# 3067M register map
File version: 1.0
Registers are 32-bit, access per field, reset 0x0 unless marked. A register's access mark holds for its fields unless they carry their own. Offsets are from the block's base; [hi:lo] are bit positions; {n}, {i} and the like mark numbered series.

## ADC0 — ADC0 peripheral interface
Base 0x18000000
Same registers: ADC1 0x18001000, ADC2 0x18002000, ADC3 0x18003000
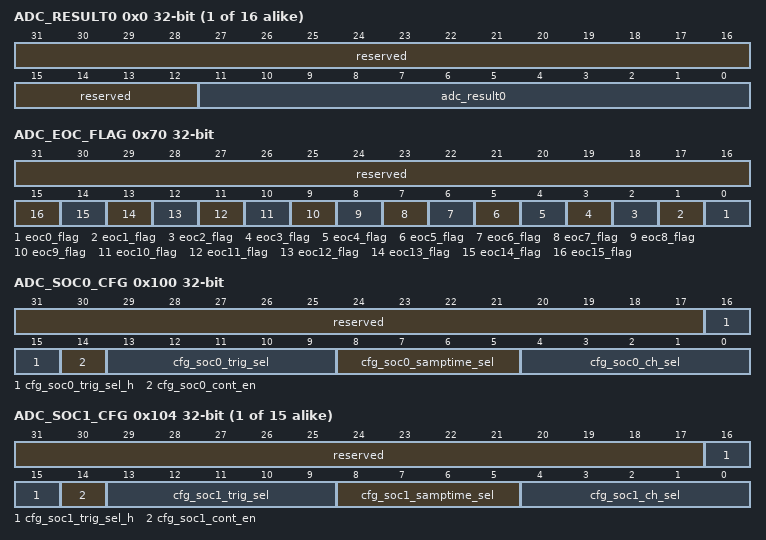
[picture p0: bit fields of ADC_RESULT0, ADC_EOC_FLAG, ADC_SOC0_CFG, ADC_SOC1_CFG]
{0x0+4i} ADC_RESULT{i} ro (i=0..15) — ADC_RESULT{i}为ADC结果寄存器{i}。
  [31:12] reserved — 保留。
  [11:0] adc_result{i} — SOC{i}结果寄存器。
0x70 ADC_EOC_FLAG — ADC_EOC_FLAG为ADC eoc状态寄存器。
  [31:16] reserved ro — 保留。
  [n] eoc{n}_flag rw write-clears (n=0..15) — SOC{n}的EOC标志寄存器。
0x100 ADC_SOC0_CFG — ADC_SOC0_CFG为ADC SOC0配置寄存器。
  [31:17] reserved ro — 保留。
  [16:15] cfg_soc0_trig_sel_h rw — SOC0触发源选择。cfg_soc0_trig_sel_h和cfg_soc0_trig_sel共同控制触发源选择。具体参见27.5.2 触发源配置。
  [14] cfg_soc0_cont_en rw — SOC0连续转换模式使能。 0：不使能； 1：使能。
  [13:9] cfg_soc0_trig_sel rw — SOC0触发源选择。cfg_soc0_trig_sel_h和cfg_soc0_trig_sel共同控制触发源选择。具体参见27.5.2 触发源配置。
  [8:5] cfg_soc0_samptime_sel rw — SOC0采样周期选择。 0x0：5clk； 0x1：7clk； 0x2：10clk； 0x3：12clk； 0x4：15clk； 0x5：22clk； 0x6：30clk； 0x7：50clk； 0x8：75clk； 0x9：100clk； 0xA：125clk； 0xB：150clk； 0xC：200clk； 0xD：300clk； 0xE：400clk； 0xF：500clk。
  [4:0] cfg_soc0_ch_sel rw — SOC0通道选择。具体请参见27.2.5 输入信号。
{0x100+4i} ADC_SOC{i}_CFG (i=1..15) — ADC_SOC{i}_CFG为ADC SOC{i}配置寄存器。
  [31:17] reserved ro — 保留。
  [16:15] cfg_soc{i}_trig_sel_h rw — SOC{i}触发源选择。
  [14] cfg_soc{i}_cont_en rw — SOC{i}连续转换模式使能。
  [13:9] cfg_soc{i}_trig_sel rw — SOC{i}触发源选择。
  [8:5] cfg_soc{i}_samptime_sel rw — SOC{i}采样周期选择。
  [4:0] cfg_soc{i}_ch_sel rw — SOC{i}通道选择。
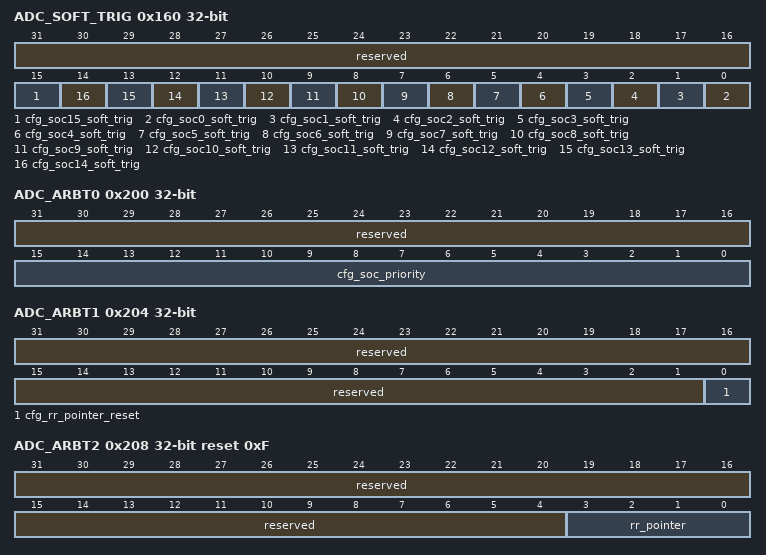
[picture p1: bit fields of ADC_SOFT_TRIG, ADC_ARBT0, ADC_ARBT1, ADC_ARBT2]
0x160 ADC_SOFT_TRIG — ADC_SOFT_TRIG为ADC软件触发寄存器。
  [31:16] reserved ro — 保留。
  [15] cfg_soc15_soft_trig rw write-1-clears — SOC15软件触发。 0：不触发； 1：触发脉冲。
  [n] cfg_soc{n}_soft_trig rw write-1-clears (n=0..14) — SOC{n}软件触发。
0x200 ADC_ARBT0 — ADC_ARBT0为ADC优先级寄存器0。
  [31:16] reserved ro — 保留。
  [15:0] cfg_soc_priority rw — SOC优先级组配置（配置对应bit位的SOC为高优先级组）。 0：轮询优先级组； 1：高优先级组。
0x204 ADC_ARBT1 — ADC_ARBT1为ADC优先级寄存器1。
  [31:1] reserved ro — 保留。
  [0] cfg_rr_pointer_reset rw write-1-clears — 轮询指针重置。 0：不重置； 1：重置指针到15。
0x208 ADC_ARBT2 ro reset 0xF — ADC_ARBT2为ADC优先级寄存器2。
  [31:4] reserved — 保留。
  [3:0] rr_pointer — 轮询指针位置。
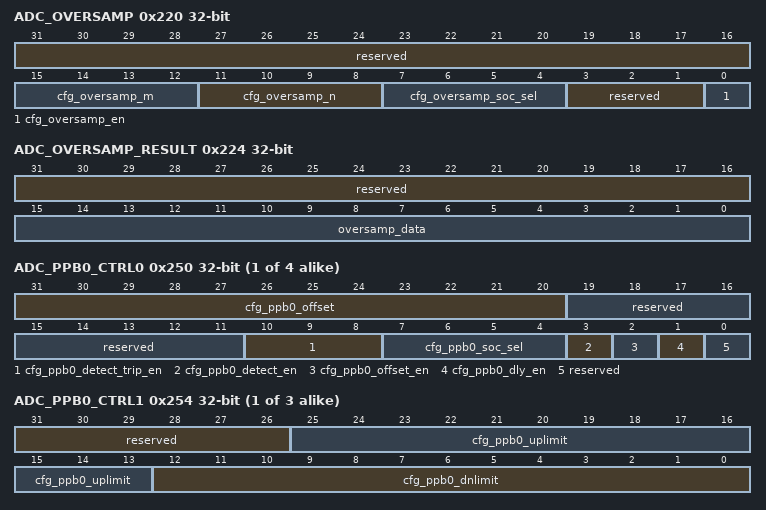
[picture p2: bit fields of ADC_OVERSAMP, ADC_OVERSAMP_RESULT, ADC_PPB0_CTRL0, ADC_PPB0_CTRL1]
0x220 ADC_OVERSAMP — ADC_OVERSAMP为ADC过采样配置寄存器。
  [31:16] reserved ro — 保留。
  [15:12] cfg_oversamp_m rw — 过采样截取精度选择，与cfg_oversamp_n联合配置，配置方式请参见27.8 过采样。
  [11:8] cfg_oversamp_n rw — 过采样累积倍数选择。 0x3：8倍； 0x4：16倍； 0x5：32倍； 0x6：64倍； 0x7：128倍； 0x8：256倍； 0x9：512倍； 0xA：1024倍； 0xB：2048倍； 其他：保留。
  [7:4] cfg_oversamp_soc_sel rw — 过采样SOC选择。 0x0：SOC0； 0x1：SOC1； … 0xF：SOC15。
  [3:1] reserved ro — 保留。
  [0] cfg_oversamp_en rw — 过采样使能。 0：不使能； 1：使能。
0x224 ADC_OVERSAMP_RESULT ro — ADC_OVERSAMP_RESULT为ADC过采样结果寄存器。
  [31:16] reserved — 保留。
  [15:0] oversamp_data — 过采样结果，低位（12bit~16bit）为有效精度。
{0x250+0x10*i} ADC_PPB{i}_CTRL0 (i=0..3) — ADC_PPB{i}_CTRL0为ADC后处理模块{i}配置寄存器0。
  [31:20] cfg_ppb{i}_offset rw — 后处理补偿offset值（有符号数，二进制补码，1bit符号位，11bit整数位）。
  [19:11] reserved ro — 保留。
  [10:8] cfg_ppb{i}_detect_trip_en rw — 后处理TRIP使能。对应bit配置1表示使能。 bit[10]：使能上阈值超限ppb{i}_uplimit_det触发ADC_EVEVT_TRIP{i}； bit[9]：使能下阈值超限ppb{i}_dnlimit_det触发ADC_EVEVT_TRIP{i}； bit[8]：使能过零点ppb{i}_zero_det触发ADC_EVEVT_TRIP{i}。
  [7:4] cfg_ppb{i}_soc_sel rw — 后处理模块SOC选择。 0x0：SOC0； 0x1：SOC1； … 0xF：SOC15。
  [3] cfg_ppb{i}_detect_en rw — 后处理阈值检测使能。 0：不使能； 1：使能。
  [2] cfg_ppb{i}_offset_en rw — 后处理offset补偿使能。 0：不使能； 1：使能。
  [1] cfg_ppb{i}_dly_en rw — 后处理采样延迟计数使能。 0：不使能； 1：使能。
  [0] reserved ro — 保留。
{0x254+0x10*i} ADC_PPB{i}_CTRL1 (i=0..2) — ADC_PPB{i}_CTRL1为ADC后处理模块{i}配置寄存器1。
  [31:26] reserved ro — 保留。
  [25:13] cfg_ppb{i}_uplimit rw — 后处理误差检测上限阈值（有符号数，二进制补码，1bit符号位，12bit整数位）。
  [12:0] cfg_ppb{i}_dnlimit rw — 后处理误差检测下限阈值（有符号数，二进制补码，1bit符号位，12bit整数位）。
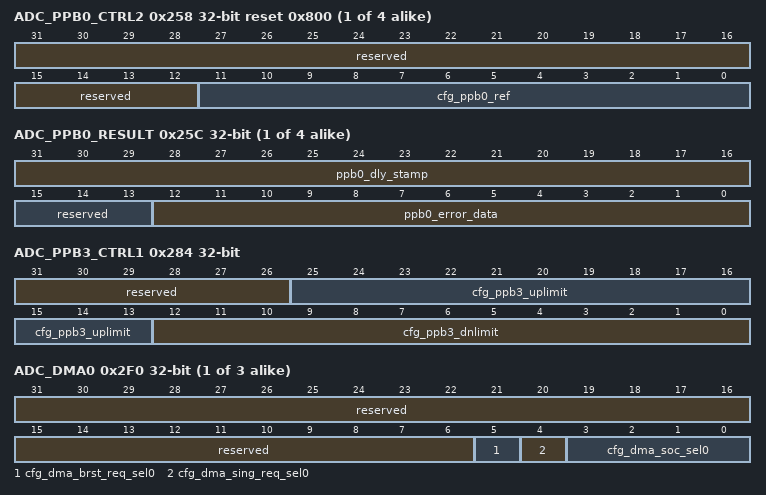
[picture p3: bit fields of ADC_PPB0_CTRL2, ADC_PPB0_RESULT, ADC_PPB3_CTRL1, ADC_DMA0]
{0x258+0x10*i} ADC_PPB{i}_CTRL2 reset 0x800 (i=0..3) — ADC_PPB{i}_CTRL2为ADC后处理模块{i}配置寄存器2。
  [31:12] reserved ro — 保留。
  [11:0] cfg_ppb{i}_ref rw — 后处理误差参考值（无符号数，12bit整数位）。
{0x25C+0x10*i} ADC_PPB{i}_RESULT ro (i=0..3) — ADC_PPB{i}_RESULT为ADC后处理模块{i}结果寄存器。
  [31:16] ppb{i}_dly_stamp — 后处理采样延迟计数值。
  [15:13] reserved — 保留。
  [12:0] ppb{i}_error_data — 后处理误差计算结果（有符号数，二进制补码，1bit符号位，12bit整数位）。
0x284 ADC_PPB3_CTRL1 — ADC_PPB3_CTRL1为ADC后处理模块3配置寄存器2。
  [31:26] reserved ro — 保留。
  [25:13] cfg_ppb3_uplimit rw — 后处理误差检测上限阈值（有符号数，二进制补码，1bit符号位，12bit整数位）。
  [12:0] cfg_ppb3_dnlimit rw — 后处理误差检测下限阈值（有符号数，二进制补码，1bit符号位，12bit整数位）。
{0x2F0+4i} ADC_DMA{i} (i=0..2) — ADC_DMA{i}为ADC DMA{i}配置寄存器。
  [31:6] reserved ro — 保留。
  [5] cfg_dma_brst_req_sel{i} rw — ADC_DMA{i} BURST请求使能。 0：不使能； 1：使能。
  [4] cfg_dma_sing_req_sel{i} rw — ADC_DMA{i} SINGLE请求使能。 0：不使能； 1：使能。
  [3:0] cfg_dma_soc_sel{i} rw — ADC_DMA{i} SOC选择。 0x0：SOC0； 0x1：SOC1； … 0xF：SOC15。
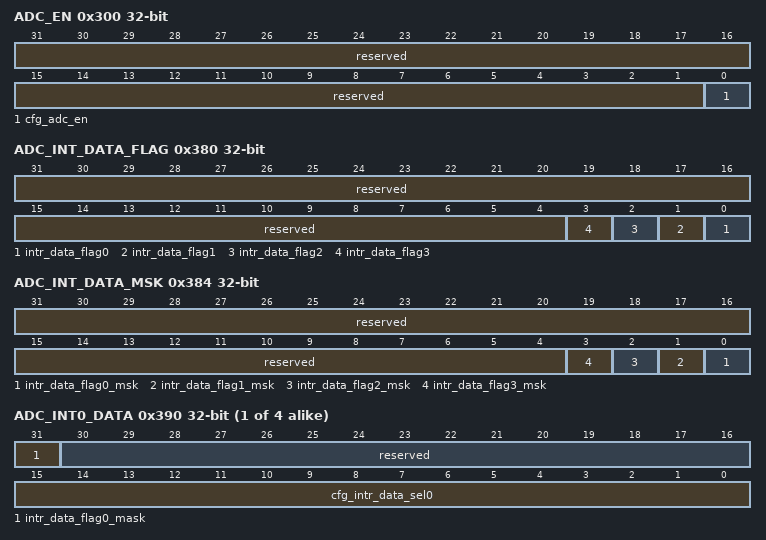
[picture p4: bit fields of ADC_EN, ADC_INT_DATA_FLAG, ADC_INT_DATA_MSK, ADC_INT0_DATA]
0x300 ADC_EN — ADC_EN为ADC使能寄存器。
  [31:1] reserved ro — 保留。
  [0] cfg_adc_en rw — ADC使能寄存器。 0：关闭； 1：使能。
0x380 ADC_INT_DATA_FLAG access not given — ADC_INT_DATA_FLAG为ADC数据中断原始状态寄存器。
  [31:4] reserved ro — 保留。
  [n] intr_data_flag{n} (n=0..3) — 数据中断原始状态寄存器。
0x384 ADC_INT_DATA_MSK ro — ADC_INT_DATA_MSK为ADC数据中断屏蔽后状态寄存器。
  [31:4] reserved — 保留。
  [n] intr_data_flag{n}_msk (n=0..3) — 数据中断屏蔽后状态寄存器。
{0x390+4i} ADC_INT{i}_DATA (i=0..3) — ADC_INT{i}_DATA为ADC数据中断配置寄存器{i}。
  [31] intr_data_flag{i}_mask rw — 数据中断{i}屏蔽寄存器。 0：屏蔽中断； 1：不屏蔽。
  [30:16] reserved ro — 保留。
  [15:0] cfg_intr_data_sel{i} rw — 数据中断{i}的SOC选择。
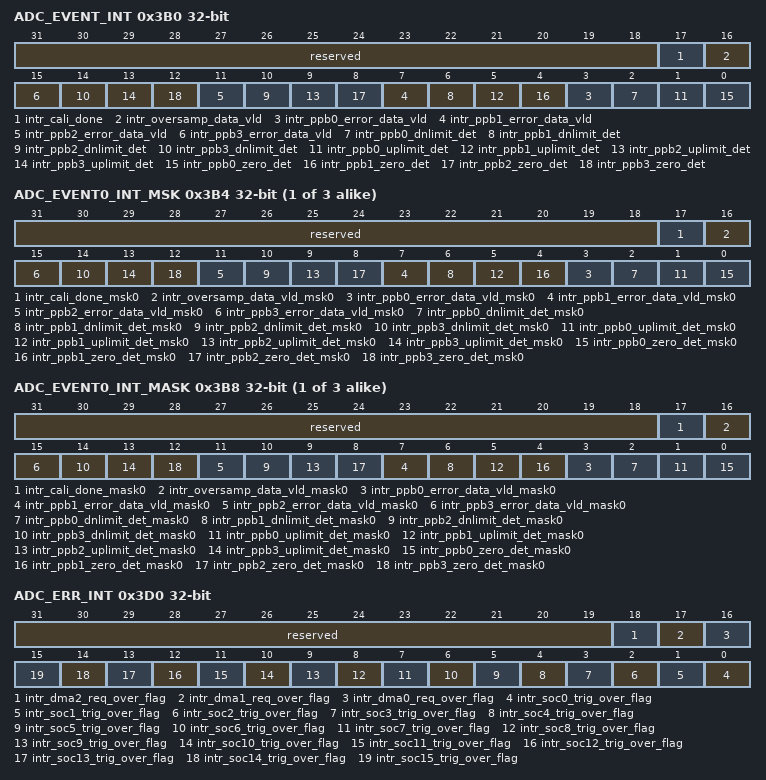
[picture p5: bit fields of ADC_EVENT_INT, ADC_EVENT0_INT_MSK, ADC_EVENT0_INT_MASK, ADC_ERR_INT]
0x3B0 ADC_EVENT_INT access not given — ADC_EVENT_INT为ADC事件中断原始状态寄存器。
  [31:18] reserved ro — 保留。
  [17] intr_cali_done — 模式1校准完成中断原始状态寄存器。
  [16] intr_oversamp_data_vld — 过采样数据有效中断原始状态寄存器。
  [4n+3] intr_ppb{n}_error_data_vld (n=0..3) — PPB{n}误差计算数据有效中断原始状态寄存器。
  [4n+2] intr_ppb{n}_dnlimit_det (n=0..3) — PPB{n}下阈值超限中断原始状态寄存器。
  [4n+1] intr_ppb{n}_uplimit_det (n=0..3) — PPB{n}上阈值超限中断原始状态寄存器。
  [4n] intr_ppb{n}_zero_det (n=0..3) — PPB{n}过零点中断原始状态寄存器。
{0x3B4+8i} ADC_EVENT{i}_INT_MSK ro (i=0..2) — ADC_EVENT{i}_INT_MSK为ADC事件中断{i}屏蔽后状态寄存器。
  [31:18] reserved — 保留。
  [17] intr_cali_done_msk{i} — ADC_EVENT{i}中断的模式1校准完成中断屏蔽后状态寄存器。
  [16] intr_oversamp_data_vld_msk{i} — ADC_EVENT{i}中断的过采样数据有效中断屏蔽后状态寄存器。
  [4n+3] intr_ppb{n}_error_data_vld_msk{i} (n=0..3) — ADC_EVENT{i}中断的PPB{n}误差计算数据有效中断屏蔽后状态寄存器。
  [4n+2] intr_ppb{n}_dnlimit_det_msk{i} (n=0..3) — ADC_EVENT{i}中断的PPB{n}下阈值超限中断屏蔽后状态寄存器。
  [4n+1] intr_ppb{n}_uplimit_det_msk{i} (n=0..3) — ADC_EVENT{i}中断的PPB{n}上阈值超限中断屏蔽后状态寄存器。
  [4n] intr_ppb{n}_zero_det_msk{i} (n=0..3) — ADC_EVENT{i}中断的PPB{n}过零点中断屏蔽后状态寄存器。
{0x3B8+8i} ADC_EVENT{i}_INT_MASK (i=0..2) — ADC_EVENT{i}_INT_MASK为ADC事件中断{i}屏蔽寄存器。
  [31:18] reserved ro — 保留。
  [17] intr_cali_done_mask{i} rw — 模式1校准完成中断屏蔽寄存器。 0：屏蔽中断； 1：不屏蔽，ADC_EVENT_INT对应位域为1时触发ADC_EVENT{i}中断。
  [16] intr_oversamp_data_vld_mask{i} rw — 过采样数据有效中断屏蔽寄存器。 0：屏蔽中断； 1：不屏蔽，ADC_EVENT_INT对应位域为1时触发ADC_EVENT{i}中断。
  [4n+3] intr_ppb{n}_error_data_vld_mask{i} rw (n=0..3) — PPB{n}误差计算数据有效中断屏蔽寄存器。 0：屏蔽中断； 1：不屏蔽，ADC_EVENT_INT对应位域为1时触发ADC_EVENT{i}中断。
  [4n+2] intr_ppb{n}_dnlimit_det_mask{i} rw (n=0..3) — PPB{n}下阈值超限中断屏蔽寄存器。 0：屏蔽中断； 1：不屏蔽，ADC_EVENT_INT对应位域为1时触发ADC_EVENT{i}中断。
  [4n+1] intr_ppb{n}_uplimit_det_mask{i} rw (n=0..3) — PPB{n}上阈值超限中断屏蔽寄存器。 0：屏蔽中断； 1：不屏蔽，ADC_EVENT_INT对应位域为1时触发ADC_EVENT{i}中断。
  [4n] intr_ppb{n}_zero_det_mask{i} rw (n=0..3) — PPB{n}过零点中断屏蔽寄存器。 0：屏蔽中断； 1：不屏蔽，ADC_EVENT_INT对应位域为1时触发ADC_EVENT{i}中断。
0x3D0 ADC_ERR_INT access not given — ADC_ERR_INT为ADC异常中断原始状态寄存器。
  [31:19] reserved ro — 保留。
  [18] intr_dma2_req_over_flag — DMA2请求溢出中断原始状态寄存器。
  [17] intr_dma1_req_over_flag — DMA1请求溢出中断原始状态寄存器。
  [16] intr_dma0_req_over_flag — DMA0请求溢出中断原始状态寄存器。
  [n] intr_soc{n}_trig_over_flag (n=0..15) — SOC{n}触发溢出中断原始状态寄存器。
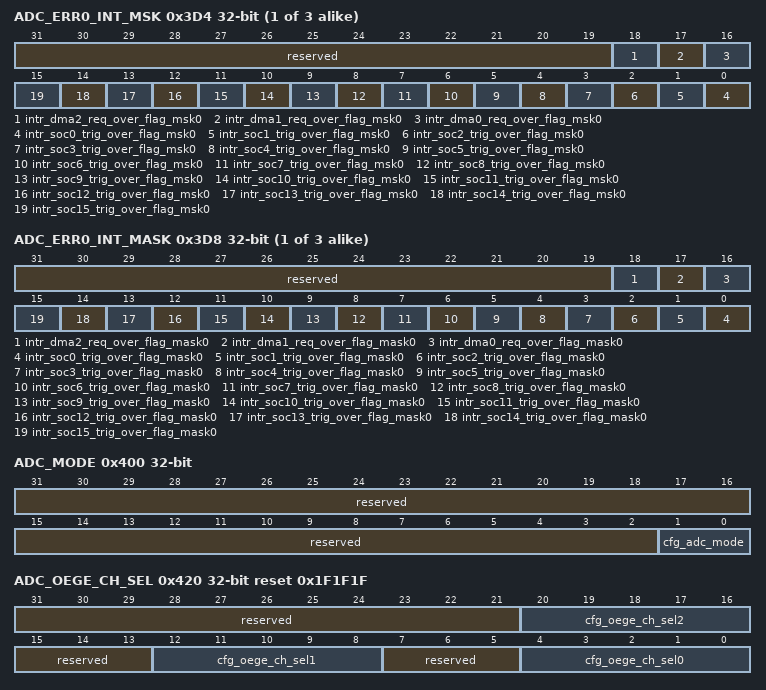
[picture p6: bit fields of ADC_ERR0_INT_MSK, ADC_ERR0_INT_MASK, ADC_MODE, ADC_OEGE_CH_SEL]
{0x3D4+8i} ADC_ERR{i}_INT_MSK ro (i=0..2) — ADC_ERR{i}_INT_MSK为ADC异常中断{i}屏蔽后状态寄存器。
  [31:19] reserved — 保留。
  [18] intr_dma2_req_over_flag_msk{i} — ADC_ERR{i}中断的DMA2请求溢出中断屏蔽后状态寄存器。
  [17] intr_dma1_req_over_flag_msk{i} — ADC_ERR{i}中断的DMA1请求溢出中断屏蔽后状态寄存器。
  [16] intr_dma0_req_over_flag_msk{i} — ADC_ERR{i}中断的DMA0请求溢出中断屏蔽后状态寄存器。
  [n] intr_soc{n}_trig_over_flag_msk{i} (n=0..15) — ADC_ERR{i}中断的SOC{n}触发溢出中断屏蔽后状态寄存器。
{0x3D8+8i} ADC_ERR{i}_INT_MASK (i=0..2) — ADC_ERR{i}_INT_MASK为ADC异常中断{i}屏蔽寄存器。
  [31:19] reserved ro — 保留。
  [18] intr_dma2_req_over_flag_mask{i} rw — DMA2请求溢出中断屏蔽寄存器。 0：屏蔽中断； 1：不屏蔽，ADC_ERR_INT对应位域为1时触发ADC_ERR{i}中断。
  [17] intr_dma1_req_over_flag_mask{i} rw — DMA1请求溢出中断屏蔽寄存器。 0：屏蔽中断； 1：不屏蔽，ADC_ERR_INT对应位域为1时触发ADC_ERR{i}中断。
  [16] intr_dma0_req_over_flag_mask{i} rw — DMA0请求溢出中断屏蔽寄存器。 0：屏蔽中断； 1：不屏蔽，ADC_ERR_INT对应位域为1时触发ADC_ERR{i}中断。
  [n] intr_soc{n}_trig_over_flag_mask{i} rw (n=0..15) — SOC{n}触发溢出中断屏蔽寄存器。 0：屏蔽中断； 1：不屏蔽，ADC_ERR_INT对应位域为1时触发ADC_ERR{i}中断。
0x400 ADC_MODE — ADC_MODE为ADC工作模式配置寄存器。
  [31:2] reserved ro — 保留。
  [1:0] cfg_adc_mode rw — ADC工作模式。 00：正常工作模式； 01：电容校准模式1； 其他：保留。
0x420 ADC_OEGE_CH_SEL reset 0x1F1F1F — ADC_OEGE_CH_SEL为ADC OE GE通道配置寄存器。
  [31:21] reserved ro — 保留。
  [20:16] cfg_oege_ch_sel2 rw — 连接通道选择（该配置选择的通道，由cfg_gain2/cfg_ofst2进行补偿）。
  [15:13] reserved ro — 保留。
  [12:8] cfg_oege_ch_sel1 rw — 连接通道选择（该配置选择的通道，由cfg_gain1/cfg_ofst1进行补偿）。
  [7:5] reserved ro — 保留。
  [4:0] cfg_oege_ch_sel0 rw — 连接通道选择（该配置选择的通道，由cfg_gain0/cfg_ofst0进行补偿）。
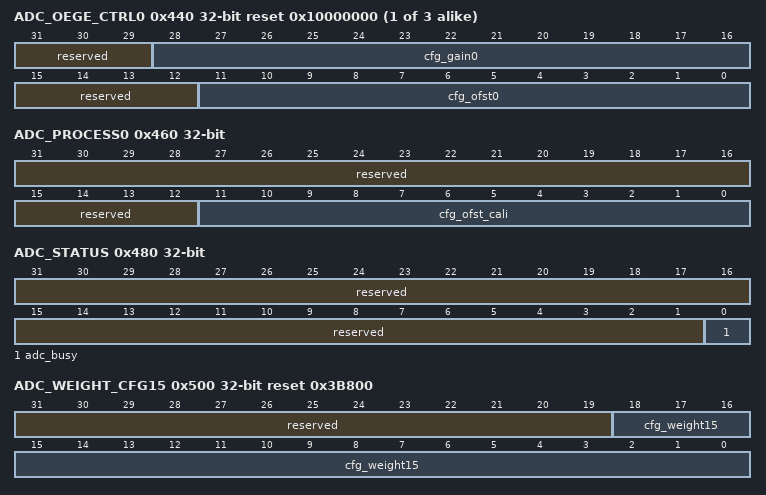
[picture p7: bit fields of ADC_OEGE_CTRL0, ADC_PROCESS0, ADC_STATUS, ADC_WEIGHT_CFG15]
{0x440+4i} ADC_OEGE_CTRL{i} reset 0x10000000 (i=0..2) — ADC_OEGE_CTRL{i}为ADC OE GE配置寄存器{i}。
  [31:29] reserved ro — 保留。
  [28:16] cfg_gain{i} rw — 软件配置GE值（无符号数，1bit整数位，12bit小数位）。
  [15:12] reserved ro — 保留。
  [11:0] cfg_ofst{i} rw — 软件配置OE值（有符号数，二进制补码，1bit符号位，10bit整数位，1bit小数位）。
0x460 ADC_PROCESS0 — ADC_PROCESS0为ADC数据处理寄存器0。
  [31:12] reserved ro — 保留。
  [11:0] cfg_ofst_cali rw — 第二级OFFSET补偿值（有符号数，二进制补码，1bit符号位，10bit整数位，1bit小数位）。
0x480 ADC_STATUS ro — ADC_STATUS为ADC状态寄存器。
  [31:1] reserved — 保留。
  [0] adc_busy — ADC工作状态。 0：空闲； 1：工作中。
0x500 ADC_WEIGHT_CFG15 reset 0x3B800 — ADC_WEIGHT_CFG15为ADC 电容权重配置寄存器。
  [31:19] reserved ro — 保留。
  [18:0] cfg_weight15 rw — fix（0,19,7）电容15权重配置值。
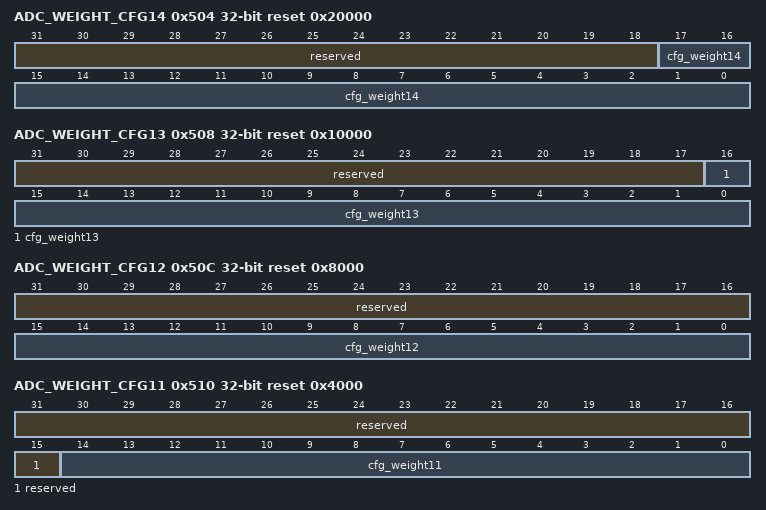
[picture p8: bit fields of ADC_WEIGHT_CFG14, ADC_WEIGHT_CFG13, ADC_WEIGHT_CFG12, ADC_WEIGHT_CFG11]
0x504 ADC_WEIGHT_CFG14 reset 0x20000 — ADC_WEIGHT_CFG14为ADC 电容权重配置寄存器。
  [31:18] reserved ro — 保留。
  [17:0] cfg_weight14 rw — fix（0,18,7）电容14权重配置值。
0x508 ADC_WEIGHT_CFG13 reset 0x10000 — ADC_WEIGHT_CFG13为ADC 电容权重配置寄存器。
  [31:17] reserved ro — 保留。
  [16:0] cfg_weight13 rw — fix（0,17,7）电容13权重配置值。
0x50C ADC_WEIGHT_CFG12 reset 0x8000 — ADC_WEIGHT_CFG12为ADC 电容权重配置寄存器。
  [31:16] reserved ro — 保留。
  [15:0] cfg_weight12 rw — fix（0,16,7）电容12权重配置值。
0x510 ADC_WEIGHT_CFG11 reset 0x4000 — ADC_WEIGHT_CFG11为ADC 电容权重配置寄存器。
  [31:15] reserved ro — 保留。
  [14:0] cfg_weight11 rw — fix（0,15,7）电容11权重配置值。
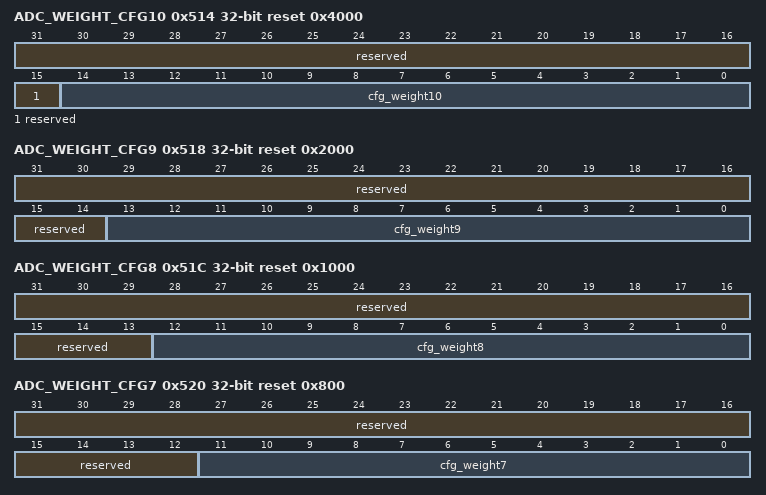
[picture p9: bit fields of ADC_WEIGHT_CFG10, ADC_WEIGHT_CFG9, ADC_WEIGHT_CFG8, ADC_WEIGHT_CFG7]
0x514 ADC_WEIGHT_CFG10 reset 0x4000 — ADC_WEIGHT_CFG10为ADC 电容权重配置寄存器。
  [31:15] reserved ro — 保留。
  [14:0] cfg_weight10 rw — fix（0,15,7）电容10权重配置值。
0x518 ADC_WEIGHT_CFG9 reset 0x2000 — ADC_WEIGHT_CFG9为ADC 电容权重配置寄存器。
  [31:14] reserved ro — 保留。
  [13:0] cfg_weight9 rw — fix（0,14,7）电容9权重配置值。
0x51C ADC_WEIGHT_CFG8 reset 0x1000 — ADC_WEIGHT_CFG8为ADC 电容权重配置寄存器。
  [31:13] reserved ro — 保留。
  [12:0] cfg_weight8 rw — fix（0,13,7）电容8权重配置值。
0x520 ADC_WEIGHT_CFG7 reset 0x800 — ADC_WEIGHT_CFG7为ADC 电容权重配置寄存器。
  [31:12] reserved ro — 保留。
  [11:0] cfg_weight7 rw — fix（0,12,7）电容7权重配置值。
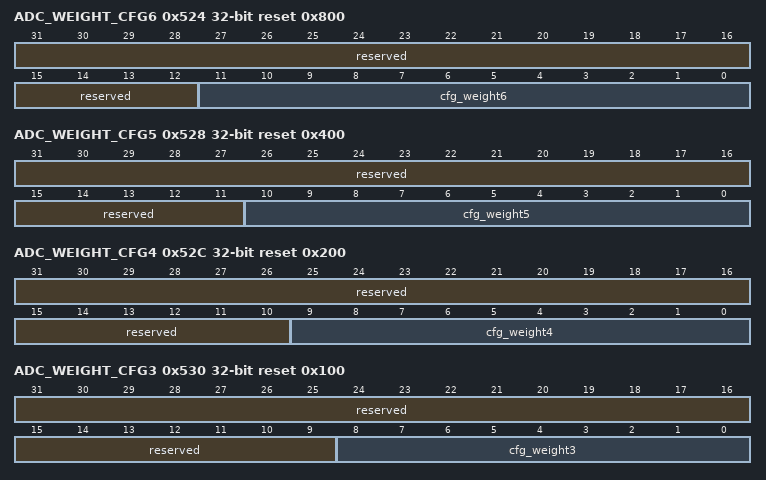
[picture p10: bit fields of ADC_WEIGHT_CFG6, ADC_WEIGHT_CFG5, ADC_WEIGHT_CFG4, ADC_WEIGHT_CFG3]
0x524 ADC_WEIGHT_CFG6 reset 0x800 — ADC_WEIGHT_CFG6为ADC 电容权重配置寄存器。
  [31:12] reserved ro — 保留。
  [11:0] cfg_weight6 rw — fix（0,12,7）电容6权重配置值。
0x528 ADC_WEIGHT_CFG5 reset 0x400 — ADC_WEIGHT_CFG5为ADC 电容权重配置寄存器。
  [31:11] reserved ro — 保留。
  [10:0] cfg_weight5 rw — fix（0,11,7）电容5权重配置值。
0x52C ADC_WEIGHT_CFG4 reset 0x200 — ADC_WEIGHT_CFG4为ADC 电容权重配置寄存器。
  [31:10] reserved ro — 保留。
  [9:0] cfg_weight4 rw — fix（0,10,7）电容4权重配置值。
0x530 ADC_WEIGHT_CFG3 reset 0x100 — ADC_WEIGHT_CFG3为ADC 电容权重配置寄存器。
  [31:9] reserved ro — 保留。
  [8:0] cfg_weight3 rw — fix（0,9,7）电容3权重配置值。
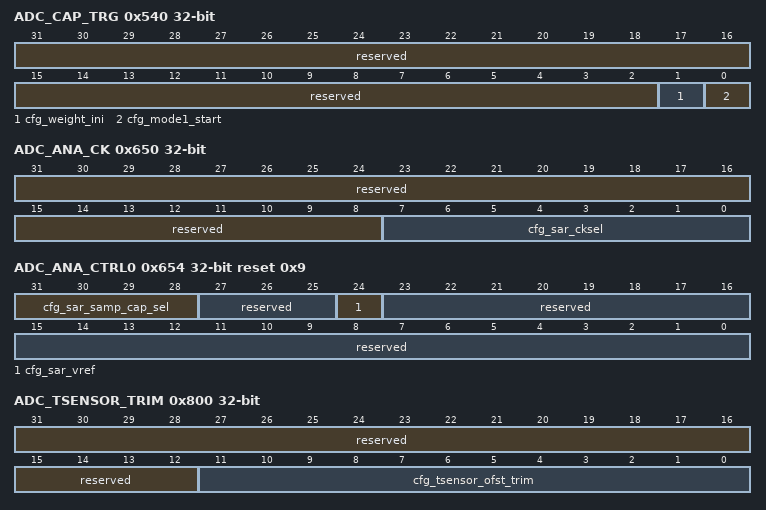
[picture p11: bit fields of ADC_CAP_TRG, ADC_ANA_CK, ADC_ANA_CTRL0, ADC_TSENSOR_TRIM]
0x540 ADC_CAP_TRG — ADC_CAP_TRG为ADC电容校准触发寄存器。
  [31:2] reserved ro — 保留。
  [1] cfg_weight_ini rw write-1-clears — 权重初始化，将软件配置权重值加载到ADC中。
  [0] cfg_mode1_start rw write-1-clears — 模式1校准触发，触发逻辑自动校准权重值。
0x650 ADC_ANA_CK — ADC_ANA_CK为ADC模拟时钟初始化控制寄存器。
  [31:8] reserved ro — 保留。
  [7:0] cfg_sar_cksel rw — 模拟时钟初始化控制。
0x654 ADC_ANA_CTRL0 reset 0x9 — ADC_ANA_CTRL0为ADC模拟寄存器0。
  [31:28] cfg_sar_samp_cap_sel rw — ADC采样电容数量配置。
  [27:25] reserved ro — 保留。
  [24] cfg_sar_vref rw — ADC VREF选择。 0：ADC选择内部VREF作为参考； 1：ADC选择外部ADCVREF作为参考。
  [23:0] reserved ro — 保留。
0x800 ADC_TSENSOR_TRIM — ADC_TSENSOR_TRIM为Tsensor trim寄存器。
  [31:12] reserved ro — 保留。
  [11:0] cfg_tsensor_ofst_trim rw — Tsensor offset补偿trim值。
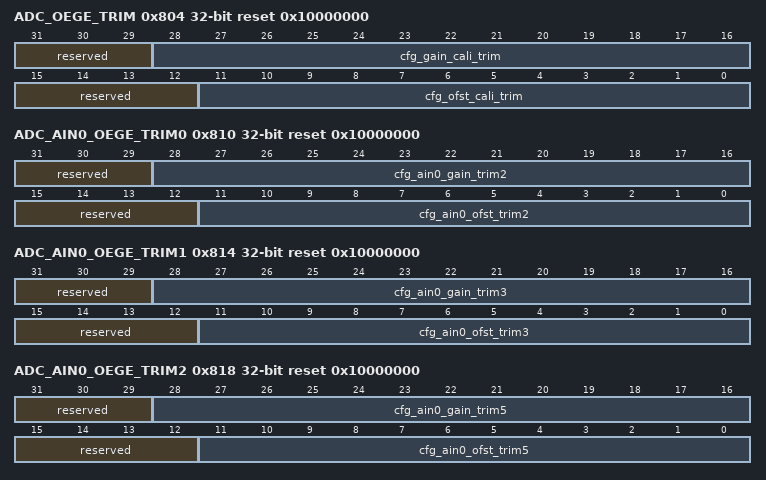
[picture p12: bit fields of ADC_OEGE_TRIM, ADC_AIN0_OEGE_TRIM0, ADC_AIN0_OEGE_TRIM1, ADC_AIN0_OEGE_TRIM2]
0x804 ADC_OEGE_TRIM reset 0x10000000 — ADC_OEGE_TRIM为ADC OE GE TRIM寄存器。
  [31:29] reserved ro — 保留。
  [28:16] cfg_gain_cali_trim rw — ADC通用GAIN校准trim值。
  [15:12] reserved ro — 保留。
  [11:0] cfg_ofst_cali_trim rw — ADC通用OFFSET校准trim值。
0x810 ADC_AIN0_OEGE_TRIM0 reset 0x10000000 — ADC_AIN0_OEGE_TRIM0为ADC AIN0 OE GE TRIM寄存器0。
  [31:29] reserved ro — 保留。
  [28:16] cfg_ain0_gain_trim2 rw — GAIN校准trim值。
  [15:12] reserved ro — 保留。
  [11:0] cfg_ain0_ofst_trim2 rw — OFFSET校准trim值。
0x814 ADC_AIN0_OEGE_TRIM1 reset 0x10000000 — ADC_AIN0_OEGE_TRIM1为ADC AIN0 OE GE TRIM寄存器1。
  [31:29] reserved ro — 保留。
  [28:16] cfg_ain0_gain_trim3 rw — GAIN校准trim值。
  [15:12] reserved ro — 保留。
  [11:0] cfg_ain0_ofst_trim3 rw — OFFSET校准trim值。
0x818 ADC_AIN0_OEGE_TRIM2 reset 0x10000000 — ADC_AIN0_OEGE_TRIM2为ADC AIN0 OE GE TRIM寄存器2。
  [31:29] reserved ro — 保留。
  [28:16] cfg_ain0_gain_trim5 rw — GAIN校准trim值。
  [15:12] reserved ro — 保留。
  [11:0] cfg_ain0_ofst_trim5 rw — OFFSET校准trim值。
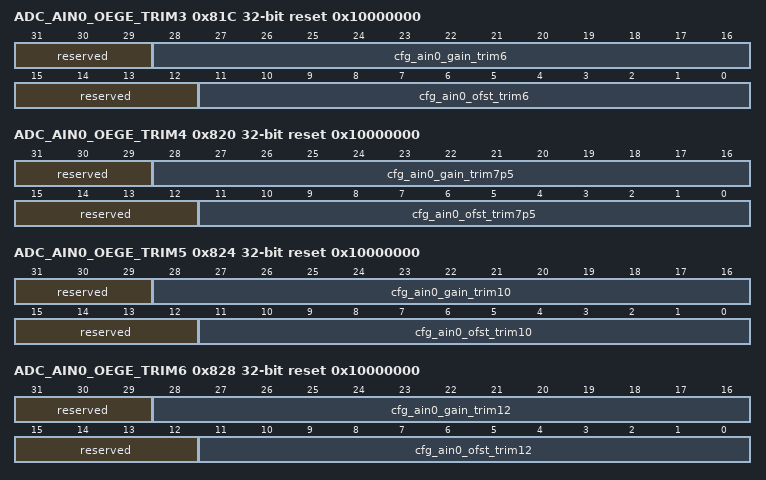
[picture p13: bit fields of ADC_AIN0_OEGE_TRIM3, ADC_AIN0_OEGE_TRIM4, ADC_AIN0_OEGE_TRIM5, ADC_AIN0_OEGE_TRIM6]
0x81C ADC_AIN0_OEGE_TRIM3 reset 0x10000000 — ADC_AIN0_OEGE_TRIM3为ADC AIN0 OE GE TRIM寄存器3。
  [31:29] reserved ro — 保留。
  [28:16] cfg_ain0_gain_trim6 rw — GAIN校准trim值。
  [15:12] reserved ro — 保留。
  [11:0] cfg_ain0_ofst_trim6 rw — OFFSET校准trim值。
0x820 ADC_AIN0_OEGE_TRIM4 reset 0x10000000 — ADC_AIN0_OEGE_TRIM4为ADC AIN0 OE GE TRIM寄存器4。
  [31:29] reserved ro — 保留。
  [28:16] cfg_ain0_gain_trim7p5 rw — GAIN校准trim值。
  [15:12] reserved ro — 保留。
  [11:0] cfg_ain0_ofst_trim7p5 rw — OFFSET校准trim值。
0x824 ADC_AIN0_OEGE_TRIM5 reset 0x10000000 — ADC_AIN0_OEGE_TRIM5为ADC AIN0 OE GE TRIM寄存器5。
  [31:29] reserved ro — 保留。
  [28:16] cfg_ain0_gain_trim10 rw — GAIN校准trim值。
  [15:12] reserved ro — 保留。
  [11:0] cfg_ain0_ofst_trim10 rw — OFFSET校准trim值。
0x828 ADC_AIN0_OEGE_TRIM6 reset 0x10000000 — ADC_AIN0_OEGE_TRIM6为ADC AIN0 OE GE TRIM寄存器6。
  [31:29] reserved ro — 保留。
  [28:16] cfg_ain0_gain_trim12 rw — GAIN校准trim值。
  [15:12] reserved ro — 保留。
  [11:0] cfg_ain0_ofst_trim12 rw — OFFSET校准trim值。
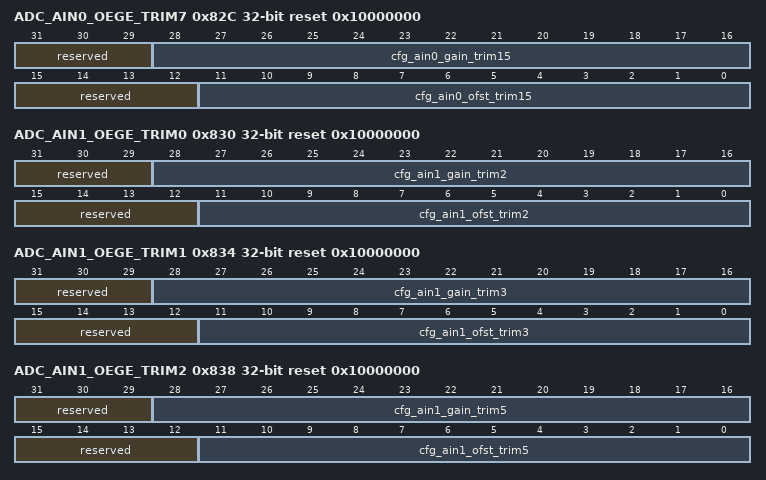
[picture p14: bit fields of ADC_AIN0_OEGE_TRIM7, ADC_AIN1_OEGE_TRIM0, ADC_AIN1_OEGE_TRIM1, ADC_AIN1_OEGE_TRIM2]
0x82C ADC_AIN0_OEGE_TRIM7 reset 0x10000000 — ADC_AIN0_OEGE_TRIM7为ADC AIN0 OE GE TRIM寄存器7。
  [31:29] reserved ro — 保留。
  [28:16] cfg_ain0_gain_trim15 rw — GAIN校准trim值。
  [15:12] reserved ro — 保留。
  [11:0] cfg_ain0_ofst_trim15 rw — OFFSET校准trim值。
0x830 ADC_AIN1_OEGE_TRIM0 reset 0x10000000 — ADC_AIN1_OEGE_TRIM0为ADC AIN1 OE GE TRIM寄存器0。
  [31:29] reserved ro — 保留。
  [28:16] cfg_ain1_gain_trim2 rw — GAIN校准trim值。
  [15:12] reserved ro — 保留。
  [11:0] cfg_ain1_ofst_trim2 rw — OFFSET校准trim值。
0x834 ADC_AIN1_OEGE_TRIM1 reset 0x10000000 — ADC_AIN1_OEGE_TRIM1为ADC AIN1 OE GE TRIM寄存器1。
  [31:29] reserved ro — 保留。
  [28:16] cfg_ain1_gain_trim3 rw — GAIN校准trim值。
  [15:12] reserved ro — 保留。
  [11:0] cfg_ain1_ofst_trim3 rw — OFFSET校准trim值。
0x838 ADC_AIN1_OEGE_TRIM2 reset 0x10000000 — ADC_AIN1_OEGE_TRIM2为ADC AIN1 OE GE TRIM寄存器2。
  [31:29] reserved ro — 保留。
  [28:16] cfg_ain1_gain_trim5 rw — GAIN校准trim值。
  [15:12] reserved ro — 保留。
  [11:0] cfg_ain1_ofst_trim5 rw — OFFSET校准trim值。
0x83C ADC_AIN1_OEGE_TRIM3 reset 0x10000000 — ADC_AIN1_OEGE_TRIM3为ADC AIN1 OE GE TRIM寄存器3。
  [31:29] reserved ro — 保留。
  [28:16] cfg_ain1_gain_trim6 rw — GAIN校准trim值。
  [15:12] reserved ro — 保留。
  [11:0] cfg_ain1_ofst_trim6 rw — OFFSET校准trim值。
0x840 ADC_AIN1_OEGE_TRIM4 reset 0x10000000 — ADC_AIN1_OEGE_TRIM4为ADC AIN1 OE GE TRIM寄存器4。
  [31:29] reserved ro — 保留。
  [28:16] cfg_ain1_gain_trim7p5 rw — GAIN校准trim值。
  [15:12] reserved ro — 保留。
  [11:0] cfg_ain1_ofst_trim7p5 rw — OFFSET校准trim值。
0x844 ADC_AIN1_OEGE_TRIM5 reset 0x10000000 — ADC_AIN1_OEGE_TRIM5为ADC AIN1 OE GE TRIM寄存器5。
  [31:29] reserved ro — 保留。
  [28:16] cfg_ain1_gain_trim10 rw — GAIN校准trim值。
  [15:12] reserved ro — 保留。
  [11:0] cfg_ain1_ofst_trim10 rw — OFFSET校准trim值。
0x848 ADC_AIN1_OEGE_TRIM6 reset 0x10000000 — ADC_AIN1_OEGE_TRIM6为ADC AIN1 OE GE TRIM寄存器6。
  [31:29] reserved ro — 保留。
  [28:16] cfg_ain1_gain_trim12 rw — GAIN校准trim值。
  [15:12] reserved ro — 保留。
  [11:0] cfg_ain1_ofst_trim12 rw — OFFSET校准trim值。
0x84C ADC_AIN1_OEGE_TRIM7 ro reset 0x10000000 — ADC_AIN1_OEGE_TRIM7为ADC AIN1 OE GE TRIM寄存器7。
  [31:29] reserved — 保留。
